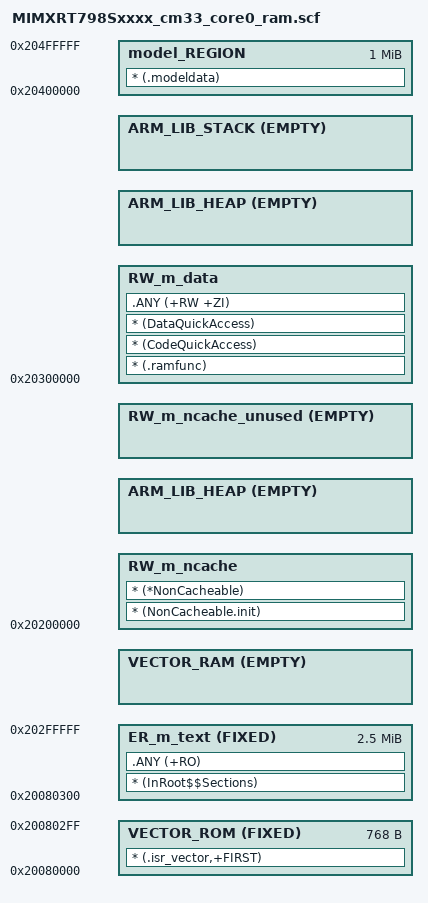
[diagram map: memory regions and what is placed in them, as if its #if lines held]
#!armclang --target=arm-arm-none-eabi -march=armv8-m.main -E -x c
/*
** ###################################################################
**     Processors:          MIMXRT798SGAWAR_cm33_core0
**                          MIMXRT798SGFOA_cm33_core0
**
**     Compiler:            Keil ARM C/C++ Compiler
**     Reference manual:    iMXRT700RM Rev.2 DraftA, 05/2024
**     Version:             rev. 2.0, 2024-05-28
**     Build:               b250227
**
**     Abstract:
**         Linker file for the Keil ARM C/C++ Compiler
**
**     Copyright 2016 Freescale Semiconductor, Inc.
**     Copyright 2016-2025 NXP
**     SPDX-License-Identifier: BSD-3-Clause
**
**     http:                 www.nxp.com
**     mail:                 support@nxp.com
**
** ###################################################################
*/


/* Sizes */
#if (defined(__stack_size__))
  #define Stack_Size                   __stack_size__
#else
  #define Stack_Size                   0x2000
#endif

#if (defined(__heap_size__))
  #define Heap_Size                    __heap_size__
#else
  #define Heap_Size                    0x0400
#endif

#if (defined(__ram_vector_table__))
  #define __ram_vector_table_size__    0x00000300
#else
  #define __ram_vector_table_size__    0x00000000
#endif

#define m_interrupts_start             0x20080000
#define m_interrupts_size              0x00000300

#define m_text_start                   0x20080300
#define m_text_size                    0x0027FD00

#define m_data_start                   0x20300000
#define m_data_size                    0x00080000

#define m_model_start                  0x20400000
#define m_model_size                   0x00100000

#define m_ncache_start                 0x20200000
#define m_ncache_size                  0x00060000

LR_m_interrupts m_interrupts_start m_text_start+m_text_size-m_interrupts_start {
  VECTOR_ROM m_interrupts_start FIXED m_interrupts_size { ; load address = execution address
    * (.isr_vector,+FIRST)
  }

  ER_m_text m_text_start FIXED m_text_size { ; load address = execution address
    * (InRoot$$Sections)
    .ANY (+RO)
  }
#if (defined(__ram_vector_table__))
  VECTOR_RAM m_interrupts_ram_start EMPTY m_interrupts_ram_size {
  }
#else
  VECTOR_RAM m_interrupts_start EMPTY 0 {
  }
#endif

#if (defined(__heap_noncacheable__))
  RW_m_data m_data_start ALIGN 4 m_data_size-Stack_Size { ; RW data
#else
  RW_m_data m_data_start ALIGN 4 m_data_size-Stack_Size-Heap_Size { ; RW data
#endif
    * (.ramfunc)
    * (CodeQuickAccess)
    * (DataQuickAccess)
    .ANY (+RW +ZI)
  }
#if (!defined(__heap_noncacheable__))
  ARM_LIB_HEAP +0 EMPTY Heap_Size {    ; Heap region growing up
  }
#endif
  ARM_LIB_STACK m_data_start+m_data_size EMPTY -Stack_Size { ; Stack region growing down
  }
#if (defined(__heap_noncacheable__))
  RW_m_ncache m_ncache_start m_ncache_size - Heap_Size { ; ncache data
#else
  RW_m_ncache m_ncache_start m_ncache_size { ; ncache data
#endif
    * (NonCacheable.init)
    * (*NonCacheable)
  }
#if (defined(__heap_noncacheable__))
  ARM_LIB_HEAP +0 EMPTY Heap_Size {    ; Heap region growing up
  }
  RW_m_ncache_unused +0 EMPTY m_ncache_size-ImageLength(RW_m_ncache)-Heap_Size { ; Empty region added for MPU configuration
  }
#else
  RW_m_ncache_unused +0 EMPTY m_ncache_size-ImageLength(RW_m_ncache) { ; Empty region added for MPU configuration
  }
#endif
  model_REGION m_model_start m_model_size {
    * (.modeldata)
  }
}
